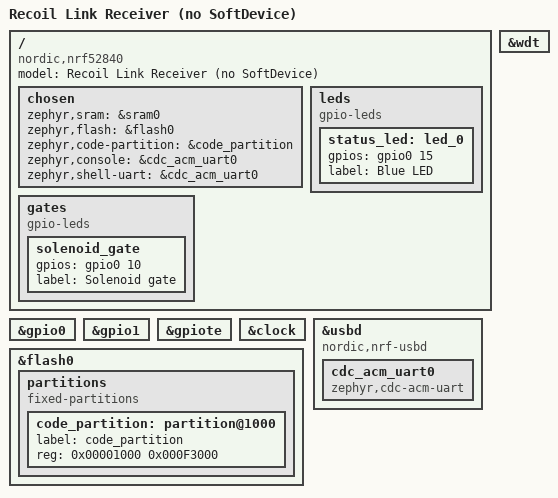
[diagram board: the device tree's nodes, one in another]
/dts-v1/;
#include <nordic/nrf52840_qiaa.dtsi>

/ {
	model = "Recoil Link Receiver (no SoftDevice)";
	compatible = "nordic,nrf52840";

	chosen {
		zephyr,sram = &sram0;
		zephyr,flash = &flash0;
		zephyr,code-partition = &code_partition;
		zephyr,console = &cdc_acm_uart0;
		zephyr,shell-uart = &cdc_acm_uart0;
	};

	leds {
		compatible = "gpio-leds";
		status_led: led_0 {
			gpios = <&gpio0 15 GPIO_ACTIVE_HIGH>;
			label = "Blue LED";
		};
	};

	gates {
		compatible = "gpio-leds";
		solenoid_gate: solenoid_gate {
			gpios = <&gpio0 10 GPIO_ACTIVE_HIGH>;
			label = "Solenoid gate";
		};
	};
};

&gpio0 {
	status = "okay";
};

&gpio1 {
	status = "okay";
};

&gpiote {
	status = "okay";
};

&clock {
	status = "okay";
};

&wdt {
	status = "okay";
};

&flash0 {
	partitions {
		compatible = "fixed-partitions";
		#address-cells = <1>;
		#size-cells = <1>;

		/* 0x00000..0x01000 is the MBR. Bootloader stays at 0xF4000. */
		code_partition: partition@1000 {
			label = "code_partition";
			reg = <0x00001000 0x000F3000>;
		};
	};
};

zephyr_udc0: &usbd {
	compatible = "nordic,nrf-usbd";
	status = "okay";

	cdc_acm_uart0: cdc_acm_uart0 {
		compatible = "zephyr,cdc-acm-uart";
	};
};
